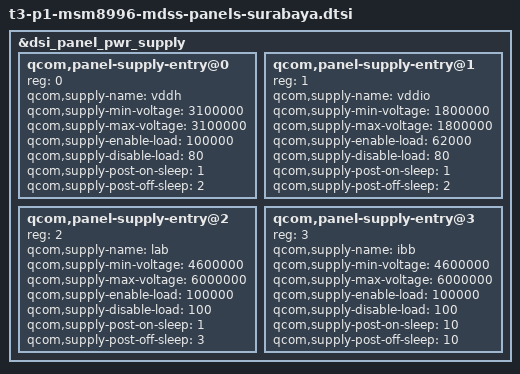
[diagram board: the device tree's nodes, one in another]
#include "dsi-panel-jdi-1080p-cmd.dtsi"
#include "dsi-panel-r63452-1080p-video.dtsi"
#include "dsi-panel-jdi-1080p-cmd_sharp.dtsi"
#include "dsi-panel-r63452-1080p-cmd.dtsi"

&dsi_panel_pwr_supply {
		qcom,panel-supply-entry@0 {
			reg = <0>;
			qcom,supply-name = "vddh";
			qcom,supply-min-voltage = <3100000>;
			qcom,supply-max-voltage = <3100000>;
			qcom,supply-enable-load = <100000>;
			qcom,supply-disable-load = <80>;
			qcom,supply-post-on-sleep = <1>;
			qcom,supply-post-off-sleep = <2>;
		};

		qcom,panel-supply-entry@1 {
			reg = <1>;
			qcom,supply-name = "vddio";
			qcom,supply-min-voltage = <1800000>;
			qcom,supply-max-voltage = <1800000>;
			qcom,supply-enable-load = <62000>;
			qcom,supply-disable-load = <80>;
			qcom,supply-post-on-sleep = <1>;
			qcom,supply-post-off-sleep = <2>;
		};

		qcom,panel-supply-entry@2 {
			reg = <2>;
			qcom,supply-name = "lab";
			qcom,supply-min-voltage = <4600000>;
			qcom,supply-max-voltage = <6000000>;
			qcom,supply-enable-load = <100000>;
			qcom,supply-disable-load = <100>;
			qcom,supply-post-on-sleep = <1>;
			qcom,supply-post-off-sleep = <3>;
		};

		qcom,panel-supply-entry@3 {
			reg = <3>;
			qcom,supply-name = "ibb";
			qcom,supply-min-voltage = <4600000>;
			qcom,supply-max-voltage = <6000000>;
			qcom,supply-enable-load = <100000>;
			qcom,supply-disable-load = <100>;
			qcom,supply-post-on-sleep = <10>;
			qcom,supply-post-off-sleep = <10>;
		};
};
